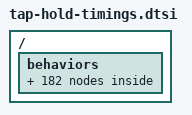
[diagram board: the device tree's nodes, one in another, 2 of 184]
#include <dt-bindings/zmk/behaviors.h>

/ {
    behaviors {

        /omit-if-no-ref/
        osm: one_shot_modifier {
            compatible = "zmk,behavior-macro-one-param";
            #binding-cells = <1>;
            tap-ms = <0>;
            wait-ms = <0>;
            bindings = <&macro_param_1to1>, <&macro_tap &sk MACRO_PLACEHOLDER>;
        };

        /omit-if-no-ref/
        osl: one_shot_layer {
            compatible = "zmk,behavior-macro-one-param";
            #binding-cells = <1>;
            tap-ms = <0>;
            wait-ms = <0>;
            bindings = <&macro_param_1to1>, <&macro_tap &sl MACRO_PLACEHOLDER>;
        };

        /omit-if-no-ref/
        mtS: mod_tap_very_slow {
            compatible = "zmk,behavior-hold-tap";
            #binding-cells = <2>;
            flavor = "hold-preferred";
            tapping-term-ms = <500>;
            bindings = <&kp>, <&kp>;
            display-name = "mod tap very slow";
        };

        /omit-if-no-ref/
        hrmS: tap_mod_very_slow {
            compatible = "zmk,behavior-hold-tap";
            #binding-cells = <2>;
            flavor = "tap-preferred";
            tapping-term-ms = <500>;
            bindings = <&kp>, <&kp>;
            display-name = "tap mod very slow";
        };

        /omit-if-no-ref/
        mts: mod_tap_slow {
            compatible = "zmk,behavior-hold-tap";
            #binding-cells = <2>;
            flavor = "hold-preferred";
            tapping-term-ms = <300>;
            bindings = <&kp>, <&kp>;
            display-name = "mod tap slow";
        };

        /omit-if-no-ref/
        hrms: tap_mod_slow {
            compatible = "zmk,behavior-hold-tap";
            #binding-cells = <2>;
            flavor = "tap-preferred";
            tapping-term-ms = <300>;
            bindings = <&kp>, <&kp>;
            display-name = "tap mod slow";
        };

        /omit-if-no-ref/
        mt: mod_tap {
            compatible = "zmk,behavior-hold-tap";
            #binding-cells = <2>;
            flavor = "hold-preferred";
            tapping-term-ms = <250>;
            bindings = <&kp>, <&kp>;
            display-name = "mod tap";
        };

        /omit-if-no-ref/
        hrm: tap_mod {
            compatible = "zmk,behavior-hold-tap";
            #binding-cells = <2>;
            flavor = "tap-preferred";
            tapping-term-ms = <250>;
            bindings = <&kp>, <&kp>;
            display-name = "tap mod";
        };

        /omit-if-no-ref/
        mtf: mod_tap_fast {
            compatible = "zmk,behavior-hold-tap";
            #binding-cells = <2>;
            flavor = "hold-preferred";
            tapping-term-ms = <200>;
            bindings = <&kp>, <&kp>;
            display-name = "mod tap fast";
        };

        /omit-if-no-ref/
        hrmf: tap_mod_fast {
            compatible = "zmk,behavior-hold-tap";
            #binding-cells = <2>;
            flavor = "tap-preferred";
            tapping-term-ms = <200>;
            bindings = <&kp>, <&kp>;
            display-name = "tap mod fast";
        };

        /omit-if-no-ref/
        mtF: mod_tap_very_fast {
            compatible = "zmk,behavior-hold-tap";
            #binding-cells = <2>;
            flavor = "hold-preferred";
            tapping-term-ms = <150>;
            bindings = <&kp>, <&kp>;
            display-name = "mod tap very fast";
        };

        /omit-if-no-ref/
        hrmF: tap_mod_very_fast {
            compatible = "zmk,behavior-hold-tap";
            #binding-cells = <2>;
            flavor = "tap-preferred";
            tapping-term-ms = <150>;
            bindings = <&kp>, <&kp>;
            display-name = "tap mod very fast";
        };

        /omit-if-no-ref/
        mtSd: mod_tap_very_slow_delayed {
            compatible = "zmk,behavior-hold-tap";
            #binding-cells = <2>;
            flavor = "hold-preferred";
            tapping-term-ms = <500>;
            require-prior-idle-ms = <125>;
            bindings = <&kp>, <&kp>;
            display-name = "mod tap very slow delayed";
        };

        /omit-if-no-ref/
        hrmSd: tap_mod_very_slow_delayed {
            compatible = "zmk,behavior-hold-tap";
            #binding-cells = <2>;
            flavor = "tap-preferred";
            tapping-term-ms = <500>;
            require-prior-idle-ms = <125>;
            bindings = <&kp>, <&kp>;
            display-name = "tap mod very slow delayed";
        };

        /omit-if-no-ref/
        mtsd: mod_tap_slow_delayed {
            compatible = "zmk,behavior-hold-tap";
            #binding-cells = <2>;
            flavor = "hold-preferred";
            tapping-term-ms = <300>;
            require-prior-idle-ms = <125>;
            bindings = <&kp>, <&kp>;
            display-name = "mod tap slow delayed";
        };

        /omit-if-no-ref/
        hrmsd: tap_mod_slow_delayed {
            compatible = "zmk,behavior-hold-tap";
            #binding-cells = <2>;
            flavor = "tap-preferred";
            tapping-term-ms = <300>;
            require-prior-idle-ms = <125>;
            bindings = <&kp>, <&kp>;
            display-name = "tap mod slow delayed";
        };

        /omit-if-no-ref/
        mtd: mod_tap_delayed {
            compatible = "zmk,behavior-hold-tap";
            #binding-cells = <2>;
            flavor = "hold-preferred";
            tapping-term-ms = <250>;
            require-prior-idle-ms = <125>;
            bindings = <&kp>, <&kp>;
            display-name = "mod tap delayed";
        };

        /omit-if-no-ref/
        hrmd: tap_mod_delayed {
            compatible = "zmk,behavior-hold-tap";
            #binding-cells = <2>;
            flavor = "tap-preferred";
            tapping-term-ms = <250>;
            require-prior-idle-ms = <125>;
            bindings = <&kp>, <&kp>;
            display-name = "tap mod delayed";
        };

        /omit-if-no-ref/
        mtfd: mod_tap_fast_delayed {
            compatible = "zmk,behavior-hold-tap";
            #binding-cells = <2>;
            flavor = "hold-preferred";
            tapping-term-ms = <200>;
            require-prior-idle-ms = <125>;
            bindings = <&kp>, <&kp>;
            display-name = "mod tap fast delayed";
        };

        /omit-if-no-ref/
        hrmfd: tap_mod_fast_delayed {
            compatible = "zmk,behavior-hold-tap";
            #binding-cells = <2>;
            flavor = "tap-preferred";
            tapping-term-ms = <200>;
            require-prior-idle-ms = <125>;
            bindings = <&kp>, <&kp>;
            display-name = "tap mod fast delayed";
        };

        /omit-if-no-ref/
        mtFd: mod_tap_very_fast_delayed {
            compatible = "zmk,behavior-hold-tap";
            #binding-cells = <2>;
            flavor = "hold-preferred";
            tapping-term-ms = <150>;
            require-prior-idle-ms = <125>;
            bindings = <&kp>, <&kp>;
            display-name = "mod tap very fast delayed";
        };

        /omit-if-no-ref/
        hrmFd: tap_mod_very_fast_delayed {
            compatible = "zmk,behavior-hold-tap";
            #binding-cells = <2>;
            flavor = "tap-preferred";
            tapping-term-ms = <150>;
            require-prior-idle-ms = <125>;
            bindings = <&kp>, <&kp>;
            display-name = "tap mod very fast delayed";
        };

        /omit-if-no-ref/
        mtSi: mod_tap_very_slow_idle {
            compatible = "zmk,behavior-hold-tap";
            #binding-cells = <2>;
            flavor = "hold-preferred";
            tapping-term-ms = <500>;
            require-prior-idle-ms = <200>;
            bindings = <&kp>, <&kp>;
            display-name = "mod tap very slow idle";
        };

        /omit-if-no-ref/
        hrmSi: tap_mod_very_slow_idle {
            compatible = "zmk,behavior-hold-tap";
            #binding-cells = <2>;
            flavor = "tap-preferred";
            tapping-term-ms = <500>;
            require-prior-idle-ms = <200>;
            bindings = <&kp>, <&kp>;
            display-name = "tap mod very slow idle";
        };

        /omit-if-no-ref/
        mtsi: mod_tap_slow_idle {
            compatible = "zmk,behavior-hold-tap";
            #binding-cells = <2>;
            flavor = "hold-preferred";
            tapping-term-ms = <300>;
            require-prior-idle-ms = <200>;
            bindings = <&kp>, <&kp>;
            display-name = "mod tap slow idle";
        };

        /omit-if-no-ref/
        hrmsi: tap_mod_slow_idle {
            compatible = "zmk,behavior-hold-tap";
            #binding-cells = <2>;
            flavor = "tap-preferred";
            tapping-term-ms = <300>;
            require-prior-idle-ms = <200>;
            bindings = <&kp>, <&kp>;
            display-name = "tap mod slow idle";
        };

        /omit-if-no-ref/
        mti: mod_tap_idle {
            compatible = "zmk,behavior-hold-tap";
            #binding-cells = <2>;
            flavor = "hold-preferred";
            tapping-term-ms = <250>;
            require-prior-idle-ms = <200>;
            bindings = <&kp>, <&kp>;
            display-name = "mod tap idle";
        };

        /omit-if-no-ref/
        hrmi: tap_mod_idle {
            compatible = "zmk,behavior-hold-tap";
            #binding-cells = <2>;
            flavor = "tap-preferred";
            tapping-term-ms = <250>;
            require-prior-idle-ms = <200>;
            bindings = <&kp>, <&kp>;
            display-name = "tap mod idle";
        };

        /omit-if-no-ref/
        mtfi: mod_tap_fast_idle {
            compatible = "zmk,behavior-hold-tap";
            #binding-cells = <2>;
            flavor = "hold-preferred";
            tapping-term-ms = <200>;
            require-prior-idle-ms = <200>;
            bindings = <&kp>, <&kp>;
            display-name = "mod tap fast idle";
        };

        /omit-if-no-ref/
        hrmfi: tap_mod_fast_idle {
            compatible = "zmk,behavior-hold-tap";
            #binding-cells = <2>;
            flavor = "tap-preferred";
            tapping-term-ms = <200>;
            require-prior-idle-ms = <200>;
            bindings = <&kp>, <&kp>;
            display-name = "tap mod fast idle";
        };

        /omit-if-no-ref/
        mtFi: mod_tap_very_fast_idle {
            compatible = "zmk,behavior-hold-tap";
            #binding-cells = <2>;
            flavor = "hold-preferred";
            tapping-term-ms = <150>;
            require-prior-idle-ms = <200>;
            bindings = <&kp>, <&kp>;
            display-name = "mod tap very fast idle";
        };

        /omit-if-no-ref/
        hrmFi: tap_mod_very_fast_idle {
            compatible = "zmk,behavior-hold-tap";
            #binding-cells = <2>;
            flavor = "tap-preferred";
            tapping-term-ms = <150>;
            require-prior-idle-ms = <200>;
            bindings = <&kp>, <&kp>;
            display-name = "tap mod very fast idle";
        };

        /omit-if-no-ref/
        mtS_sk: mod_tap_very_slow_sticky_key {
            compatible = "zmk,behavior-hold-tap";
            #binding-cells = <2>;
            flavor = "hold-preferred";
            tapping-term-ms = <500>;
            bindings = <&kp>, <&osm>;
            display-name = "mod tap very slow sticky key";
        };

        /omit-if-no-ref/
        hrmS_sk: tap_mod_very_slow_sticky_key {
            compatible = "zmk,behavior-hold-tap";
            #binding-cells = <2>;
            flavor = "tap-preferred";
            tapping-term-ms = <500>;
            bindings = <&kp>, <&osm>;
            display-name = "tap mod very slow sticky key";
        };

        /omit-if-no-ref/
        mts_sk: mod_tap_slow_sticky_key {
            compatible = "zmk,behavior-hold-tap";
            #binding-cells = <2>;
            flavor = "hold-preferred";
            tapping-term-ms = <300>;
            bindings = <&kp>, <&osm>;
            display-name = "mod tap slow sticky key";
        };

        /omit-if-no-ref/
        hrms_sk: tap_mod_slow_sticky_key {
            compatible = "zmk,behavior-hold-tap";
            #binding-cells = <2>;
            flavor = "tap-preferred";
            tapping-term-ms = <300>;
            bindings = <&kp>, <&osm>;
            display-name = "tap mod slow sticky key";
        };

        /omit-if-no-ref/
        mt_sk: mod_tap_sticky_key {
            compatible = "zmk,behavior-hold-tap";
            #binding-cells = <2>;
            flavor = "hold-preferred";
            tapping-term-ms = <250>;
            bindings = <&kp>, <&osm>;
            display-name = "mod tap sticky key";
        };

        /omit-if-no-ref/
        hrm_sk: tap_mod_sticky_key {
            compatible = "zmk,behavior-hold-tap";
            #binding-cells = <2>;
            flavor = "tap-preferred";
            tapping-term-ms = <250>;
            bindings = <&kp>, <&osm>;
            display-name = "tap mod sticky key";
        };

        /omit-if-no-ref/
        mtf_sk: mod_tap_fast_sticky_key {
            compatible = "zmk,behavior-hold-tap";
            #binding-cells = <2>;
            flavor = "hold-preferred";
            tapping-term-ms = <200>;
            bindings = <&kp>, <&osm>;
            display-name = "mod tap fast sticky key";
        };

        /omit-if-no-ref/
        hrmf_sk: tap_mod_fast_sticky_key {
            compatible = "zmk,behavior-hold-tap";
            #binding-cells = <2>;
            flavor = "tap-preferred";
            tapping-term-ms = <200>;
            bindings = <&kp>, <&osm>;
            display-name = "tap mod fast sticky key";
        };

        /omit-if-no-ref/
        mtF_sk: mod_tap_very_fast_sticky_key {
            compatible = "zmk,behavior-hold-tap";
            #binding-cells = <2>;
            flavor = "hold-preferred";
            tapping-term-ms = <150>;
            bindings = <&kp>, <&osm>;
            display-name = "mod tap very fast sticky key";
        };

        /omit-if-no-ref/
        hrmF_sk: tap_mod_very_fast_sticky_key {
            compatible = "zmk,behavior-hold-tap";
            #binding-cells = <2>;
            flavor = "tap-preferred";
            tapping-term-ms = <150>;
            bindings = <&kp>, <&osm>;
            display-name = "tap mod very fast sticky key";
        };

        /omit-if-no-ref/
        mtSd_sk: mod_tap_very_slow_delayed_sticky_key {
            compatible = "zmk,behavior-hold-tap";
            #binding-cells = <2>;
            flavor = "hold-preferred";
            tapping-term-ms = <500>;
            require-prior-idle-ms = <125>;
            bindings = <&kp>, <&osm>;
            display-name = "mod tap very slow delayed sticky key";
        };

        /omit-if-no-ref/
        hrmSd_sk: tap_mod_very_slow_delayed_sticky_key {
            compatible = "zmk,behavior-hold-tap";
            #binding-cells = <2>;
            flavor = "tap-preferred";
            tapping-term-ms = <500>;
            require-prior-idle-ms = <125>;
            bindings = <&kp>, <&osm>;
            display-name = "tap mod very slow delayed sticky key";
        };

        /omit-if-no-ref/
        mtsd_sk: mod_tap_slow_delayed_sticky_key {
            compatible = "zmk,behavior-hold-tap";
            #binding-cells = <2>;
            flavor = "hold-preferred";
            tapping-term-ms = <300>;
            require-prior-idle-ms = <125>;
            bindings = <&kp>, <&osm>;
            display-name = "mod tap slow delayed sticky key";
        };

        /omit-if-no-ref/
        hrmsd_sk: tap_mod_slow_delayed_sticky_key {
            compatible = "zmk,behavior-hold-tap";
            #binding-cells = <2>;
            flavor = "tap-preferred";
            tapping-term-ms = <300>;
            require-prior-idle-ms = <125>;
            bindings = <&kp>, <&osm>;
            display-name = "tap mod slow delayed sticky key";
        };

        /omit-if-no-ref/
        mtd_sk: mod_tap_delayed_sticky_key {
            compatible = "zmk,behavior-hold-tap";
            #binding-cells = <2>;
            flavor = "hold-preferred";
            tapping-term-ms = <250>;
            require-prior-idle-ms = <125>;
            bindings = <&kp>, <&osm>;
            display-name = "mod tap delayed sticky key";
        };

        /omit-if-no-ref/
        hrmd_sk: tap_mod_delayed_sticky_key {
            compatible = "zmk,behavior-hold-tap";
            #binding-cells = <2>;
            flavor = "tap-preferred";
            tapping-term-ms = <250>;
            require-prior-idle-ms = <125>;
            bindings = <&kp>, <&osm>;
            display-name = "tap mod delayed sticky key";
        };

        /omit-if-no-ref/
        mtfd_sk: mod_tap_fast_delayed_sticky_key {
            compatible = "zmk,behavior-hold-tap";
            #binding-cells = <2>;
            flavor = "hold-preferred";
            tapping-term-ms = <200>;
            require-prior-idle-ms = <125>;
            bindings = <&kp>, <&osm>;
            display-name = "mod tap fast delayed sticky key";
        };

        /omit-if-no-ref/
        hrmfd_sk: tap_mod_fast_delayed_sticky_key {
            compatible = "zmk,behavior-hold-tap";
            #binding-cells = <2>;
            flavor = "tap-preferred";
            tapping-term-ms = <200>;
            require-prior-idle-ms = <125>;
            bindings = <&kp>, <&osm>;
            display-name = "tap mod fast delayed sticky key";
        };

        /omit-if-no-ref/
        mtFd_sk: mod_tap_very_fast_delayed_sticky_key {
            compatible = "zmk,behavior-hold-tap";
            #binding-cells = <2>;
            flavor = "hold-preferred";
            tapping-term-ms = <150>;
            require-prior-idle-ms = <125>;
            bindings = <&kp>, <&osm>;
            display-name = "mod tap very fast delayed sticky key";
        };

        /omit-if-no-ref/
        hrmFd_sk: tap_mod_very_fast_delayed_sticky_key {
            compatible = "zmk,behavior-hold-tap";
            #binding-cells = <2>;
            flavor = "tap-preferred";
            tapping-term-ms = <150>;
            require-prior-idle-ms = <125>;
            bindings = <&kp>, <&osm>;
            display-name = "tap mod very fast delayed sticky key";
        };

        /omit-if-no-ref/
        mtSi_sk: mod_tap_very_slow_idle_sticky_key {
            compatible = "zmk,behavior-hold-tap";
            #binding-cells = <2>;
            flavor = "hold-preferred";
            tapping-term-ms = <500>;
            require-prior-idle-ms = <200>;
            bindings = <&kp>, <&osm>;
            display-name = "mod tap very slow idle sticky key";
        };

        /omit-if-no-ref/
        hrmSi_sk: tap_mod_very_slow_idle_sticky_key {
            compatible = "zmk,behavior-hold-tap";
            #binding-cells = <2>;
            flavor = "tap-preferred";
            tapping-term-ms = <500>;
            require-prior-idle-ms = <200>;
            bindings = <&kp>, <&osm>;
            display-name = "tap mod very slow idle sticky key";
        };

        /omit-if-no-ref/
        mtsi_sk: mod_tap_slow_idle_sticky_key {
            compatible = "zmk,behavior-hold-tap";
            #binding-cells = <2>;
            flavor = "hold-preferred";
            tapping-term-ms = <300>;
            require-prior-idle-ms = <200>;
            bindings = <&kp>, <&osm>;
            display-name = "mod tap slow idle sticky key";
        };

        /omit-if-no-ref/
        hrmsi_sk: tap_mod_slow_idle_sticky_key {
            compatible = "zmk,behavior-hold-tap";
            #binding-cells = <2>;
            flavor = "tap-preferred";
            tapping-term-ms = <300>;
            require-prior-idle-ms = <200>;
            bindings = <&kp>, <&osm>;
            display-name = "tap mod slow idle sticky key";
        };

        /omit-if-no-ref/
        mti_sk: mod_tap_idle_sticky_key {
            compatible = "zmk,behavior-hold-tap";
            #binding-cells = <2>;
            flavor = "hold-preferred";
            tapping-term-ms = <250>;
            require-prior-idle-ms = <200>;
            bindings = <&kp>, <&osm>;
            display-name = "mod tap idle sticky key";
        };

        /omit-if-no-ref/
        hrmi_sk: tap_mod_idle_sticky_key {
            compatible = "zmk,behavior-hold-tap";
            #binding-cells = <2>;
            flavor = "tap-preferred";
            tapping-term-ms = <250>;
            require-prior-idle-ms = <200>;
            bindings = <&kp>, <&osm>;
            display-name = "tap mod idle sticky key";
        };

        /omit-if-no-ref/
        mtfi_sk: mod_tap_fast_idle_sticky_key {
            compatible = "zmk,behavior-hold-tap";
            #binding-cells = <2>;
            flavor = "hold-preferred";
            tapping-term-ms = <200>;
            require-prior-idle-ms = <200>;
            bindings = <&kp>, <&osm>;
            display-name = "mod tap fast idle sticky key";
        };

        /omit-if-no-ref/
        hrmfi_sk: tap_mod_fast_idle_sticky_key {
            compatible = "zmk,behavior-hold-tap";
            #binding-cells = <2>;
            flavor = "tap-preferred";
            tapping-term-ms = <200>;
            require-prior-idle-ms = <200>;
            bindings = <&kp>, <&osm>;
            display-name = "tap mod fast idle sticky key";
        };

        /omit-if-no-ref/
        mtFi_sk: mod_tap_very_fast_idle_sticky_key {
            compatible = "zmk,behavior-hold-tap";
            #binding-cells = <2>;
            flavor = "hold-preferred";
            tapping-term-ms = <150>;
            require-prior-idle-ms = <200>;
            bindings = <&kp>, <&osm>;
            display-name = "mod tap very fast idle sticky key";
        };

        /omit-if-no-ref/
        hrmFi_sk: tap_mod_very_fast_idle_sticky_key {
            compatible = "zmk,behavior-hold-tap";
            #binding-cells = <2>;
            flavor = "tap-preferred";
            tapping-term-ms = <150>;
            require-prior-idle-ms = <200>;
            bindings = <&kp>, <&osm>;
            display-name = "tap mod very fast idle sticky key";
        };

        /omit-if-no-ref/
        mtS_sl: mod_tap_very_slow_sticky_layer {
            compatible = "zmk,behavior-hold-tap";
            #binding-cells = <2>;
            flavor = "hold-preferred";
            tapping-term-ms = <500>;
            bindings = <&kp>, <&osl>;
            display-name = "mod tap very slow sticky layer";
        };

        /omit-if-no-ref/
        hrmS_sl: tap_mod_very_slow_sticky_layer {
            compatible = "zmk,behavior-hold-tap";
            #binding-cells = <2>;
            flavor = "tap-preferred";
            tapping-term-ms = <500>;
            bindings = <&kp>, <&osl>;
            display-name = "tap mod very slow sticky layer";
        };

        /omit-if-no-ref/
        mts_sl: mod_tap_slow_sticky_layer {
            compatible = "zmk,behavior-hold-tap";
            #binding-cells = <2>;
            flavor = "hold-preferred";
            tapping-term-ms = <300>;
            bindings = <&kp>, <&osl>;
            display-name = "mod tap slow sticky layer";
        };

        /omit-if-no-ref/
        hrms_sl: tap_mod_slow_sticky_layer {
            compatible = "zmk,behavior-hold-tap";
            #binding-cells = <2>;
            flavor = "tap-preferred";
            tapping-term-ms = <300>;
            bindings = <&kp>, <&osl>;
            display-name = "tap mod slow sticky layer";
        };

        /omit-if-no-ref/
        mt_sl: mod_tap_sticky_layer {
            compatible = "zmk,behavior-hold-tap";
            #binding-cells = <2>;
            flavor = "hold-preferred";
            tapping-term-ms = <250>;
            bindings = <&kp>, <&osl>;
            display-name = "mod tap sticky layer";
        };

        /omit-if-no-ref/
        hrm_sl: tap_mod_sticky_layer {
            compatible = "zmk,behavior-hold-tap";
            #binding-cells = <2>;
            flavor = "tap-preferred";
            tapping-term-ms = <250>;
            bindings = <&kp>, <&osl>;
            display-name = "tap mod sticky layer";
        };

        /omit-if-no-ref/
        mtf_sl: mod_tap_fast_sticky_layer {
            compatible = "zmk,behavior-hold-tap";
            #binding-cells = <2>;
            flavor = "hold-preferred";
            tapping-term-ms = <200>;
            bindings = <&kp>, <&osl>;
            display-name = "mod tap fast sticky layer";
        };

        /omit-if-no-ref/
        hrmf_sl: tap_mod_fast_sticky_layer {
            compatible = "zmk,behavior-hold-tap";
            #binding-cells = <2>;
            flavor = "tap-preferred";
            tapping-term-ms = <200>;
            bindings = <&kp>, <&osl>;
            display-name = "tap mod fast sticky layer";
        };

        /omit-if-no-ref/
        mtF_sl: mod_tap_very_fast_sticky_layer {
            compatible = "zmk,behavior-hold-tap";
            #binding-cells = <2>;
            flavor = "hold-preferred";
            tapping-term-ms = <150>;
            bindings = <&kp>, <&osl>;
            display-name = "mod tap very fast sticky layer";
        };

        /omit-if-no-ref/
        hrmF_sl: tap_mod_very_fast_sticky_layer {
            compatible = "zmk,behavior-hold-tap";
            #binding-cells = <2>;
            flavor = "tap-preferred";
            tapping-term-ms = <150>;
            bindings = <&kp>, <&osl>;
            display-name = "tap mod very fast sticky layer";
        };

        /omit-if-no-ref/
        mtSd_sl: mod_tap_very_slow_delayed_sticky_layer {
            compatible = "zmk,behavior-hold-tap";
            #binding-cells = <2>;
            flavor = "hold-preferred";
            tapping-term-ms = <500>;
            require-prior-idle-ms = <125>;
            bindings = <&kp>, <&osl>;
            display-name = "mod tap very slow delayed sticky layer";
        };

        /omit-if-no-ref/
        hrmSd_sl: tap_mod_very_slow_delayed_sticky_layer {
            compatible = "zmk,behavior-hold-tap";
            #binding-cells = <2>;
            flavor = "tap-preferred";
            tapping-term-ms = <500>;
            require-prior-idle-ms = <125>;
            bindings = <&kp>, <&osl>;
            display-name = "tap mod very slow delayed sticky layer";
        };

        /omit-if-no-ref/
        mtsd_sl: mod_tap_slow_delayed_sticky_layer {
            compatible = "zmk,behavior-hold-tap";
            #binding-cells = <2>;
            flavor = "hold-preferred";
            tapping-term-ms = <300>;
            require-prior-idle-ms = <125>;
            bindings = <&kp>, <&osl>;
            display-name = "mod tap slow delayed sticky layer";
        };

        /omit-if-no-ref/
        hrmsd_sl: tap_mod_slow_delayed_sticky_layer {
            compatible = "zmk,behavior-hold-tap";
            #binding-cells = <2>;
            flavor = "tap-preferred";
            tapping-term-ms = <300>;
            require-prior-idle-ms = <125>;
            bindings = <&kp>, <&osl>;
            display-name = "tap mod slow delayed sticky layer";
        };

        /omit-if-no-ref/
        mtd_sl: mod_tap_delayed_sticky_layer {
            compatible = "zmk,behavior-hold-tap";
            #binding-cells = <2>;
            flavor = "hold-preferred";
            tapping-term-ms = <250>;
            require-prior-idle-ms = <125>;
            bindings = <&kp>, <&osl>;
            display-name = "mod tap delayed sticky layer";
        };

        /omit-if-no-ref/
        hrmd_sl: tap_mod_delayed_sticky_layer {
            compatible = "zmk,behavior-hold-tap";
            #binding-cells = <2>;
            flavor = "tap-preferred";
            tapping-term-ms = <250>;
            require-prior-idle-ms = <125>;
            bindings = <&kp>, <&osl>;
            display-name = "tap mod delayed sticky layer";
        };

        /omit-if-no-ref/
        mtfd_sl: mod_tap_fast_delayed_sticky_layer {
            compatible = "zmk,behavior-hold-tap";
            #binding-cells = <2>;
            flavor = "hold-preferred";
            tapping-term-ms = <200>;
            require-prior-idle-ms = <125>;
            bindings = <&kp>, <&osl>;
            display-name = "mod tap fast delayed sticky layer";
        };

        /omit-if-no-ref/
        hrmfd_sl: tap_mod_fast_delayed_sticky_layer {
            compatible = "zmk,behavior-hold-tap";
            #binding-cells = <2>;
            flavor = "tap-preferred";
            tapping-term-ms = <200>;
            require-prior-idle-ms = <125>;
            bindings = <&kp>, <&osl>;
            display-name = "tap mod fast delayed sticky layer";
        };

        /omit-if-no-ref/
        mtFd_sl: mod_tap_very_fast_delayed_sticky_layer {
            compatible = "zmk,behavior-hold-tap";
            #binding-cells = <2>;
            flavor = "hold-preferred";
            tapping-term-ms = <150>;
            require-prior-idle-ms = <125>;
            bindings = <&kp>, <&osl>;
            display-name = "mod tap very fast delayed sticky layer";
        };

        /omit-if-no-ref/
        hrmFd_sl: tap_mod_very_fast_delayed_sticky_layer {
            compatible = "zmk,behavior-hold-tap";
            #binding-cells = <2>;
            flavor = "tap-preferred";
            tapping-term-ms = <150>;
            require-prior-idle-ms = <125>;
            bindings = <&kp>, <&osl>;
            display-name = "tap mod very fast delayed sticky layer";
        };

        /omit-if-no-ref/
        mtSi_sl: mod_tap_very_slow_idle_sticky_layer {
            compatible = "zmk,behavior-hold-tap";
            #binding-cells = <2>;
            flavor = "hold-preferred";
            tapping-term-ms = <500>;
            require-prior-idle-ms = <200>;
            bindings = <&kp>, <&osl>;
            display-name = "mod tap very slow idle sticky layer";
        };

        /omit-if-no-ref/
        hrmSi_sl: tap_mod_very_slow_idle_sticky_layer {
            compatible = "zmk,behavior-hold-tap";
            #binding-cells = <2>;
            flavor = "tap-preferred";
            tapping-term-ms = <500>;
            require-prior-idle-ms = <200>;
            bindings = <&kp>, <&osl>;
            display-name = "tap mod very slow idle sticky layer";
        };

        /omit-if-no-ref/
        mtsi_sl: mod_tap_slow_idle_sticky_layer {
            compatible = "zmk,behavior-hold-tap";
            #binding-cells = <2>;
            flavor = "hold-preferred";
            tapping-term-ms = <300>;
            require-prior-idle-ms = <200>;
            bindings = <&kp>, <&osl>;
            display-name = "mod tap slow idle sticky layer";
        };

        /omit-if-no-ref/
        hrmsi_sl: tap_mod_slow_idle_sticky_layer {
            compatible = "zmk,behavior-hold-tap";
            #binding-cells = <2>;
            flavor = "tap-preferred";
            tapping-term-ms = <300>;
            require-prior-idle-ms = <200>;
            bindings = <&kp>, <&osl>;
            display-name = "tap mod slow idle sticky layer";
        };

        /omit-if-no-ref/
        mti_sl: mod_tap_idle_sticky_layer {
            compatible = "zmk,behavior-hold-tap";
            #binding-cells = <2>;
            flavor = "hold-preferred";
            tapping-term-ms = <250>;
            require-prior-idle-ms = <200>;
            bindings = <&kp>, <&osl>;
            display-name = "mod tap idle sticky layer";
        };

        /omit-if-no-ref/
        hrmi_sl: tap_mod_idle_sticky_layer {
            compatible = "zmk,behavior-hold-tap";
            #binding-cells = <2>;
            flavor = "tap-preferred";
            tapping-term-ms = <250>;
            require-prior-idle-ms = <200>;
            bindings = <&kp>, <&osl>;
            display-name = "tap mod idle sticky layer";
        };

        /omit-if-no-ref/
        mtfi_sl: mod_tap_fast_idle_sticky_layer {
            compatible = "zmk,behavior-hold-tap";
            #binding-cells = <2>;
            flavor = "hold-preferred";
            tapping-term-ms = <200>;
            require-prior-idle-ms = <200>;
            bindings = <&kp>, <&osl>;
            display-name = "mod tap fast idle sticky layer";
        };

        /omit-if-no-ref/
        hrmfi_sl: tap_mod_fast_idle_sticky_layer {
            compatible = "zmk,behavior-hold-tap";
            #binding-cells = <2>;
            flavor = "tap-preferred";
            tapping-term-ms = <200>;
            require-prior-idle-ms = <200>;
            bindings = <&kp>, <&osl>;
            display-name = "tap mod fast idle sticky layer";
        };

        /omit-if-no-ref/
        mtFi_sl: mod_tap_very_fast_idle_sticky_layer {
            compatible = "zmk,behavior-hold-tap";
            #binding-cells = <2>;
            flavor = "hold-preferred";
            tapping-term-ms = <150>;
            require-prior-idle-ms = <200>;
            bindings = <&kp>, <&osl>;
            display-name = "mod tap very fast idle sticky layer";
        };

        /omit-if-no-ref/
        hrmFi_sl: tap_mod_very_fast_idle_sticky_layer {
            compatible = "zmk,behavior-hold-tap";
            #binding-cells = <2>;
            flavor = "tap-preferred";
            tapping-term-ms = <150>;
            require-prior-idle-ms = <200>;
            bindings = <&kp>, <&osl>;
            display-name = "tap mod very fast idle sticky layer";
        };

        /omit-if-no-ref/
        ltS: layer_tap_very_slow {
            compatible = "zmk,behavior-hold-tap";
            #binding-cells = <2>;
            flavor = "hold-preferred";
            tapping-term-ms = <500>;
            bindings = <&mo>, <&kp>;
            display-name = "layer tap very slow";
        };

        /omit-if-no-ref/
        hrlS: tap_layer_very_slow {
            compatible = "zmk,behavior-hold-tap";
            #binding-cells = <2>;
            flavor = "tap-preferred";
            tapping-term-ms = <500>;
            bindings = <&mo>, <&kp>;
            display-name = "tap layer very slow";
        };

        /omit-if-no-ref/
        lts: layer_tap_slow {
            compatible = "zmk,behavior-hold-tap";
            #binding-cells = <2>;
            flavor = "hold-preferred";
            tapping-term-ms = <300>;
            bindings = <&mo>, <&kp>;
            display-name = "layer tap slow";
        };

        /omit-if-no-ref/
        hrls: tap_layer_slow {
            compatible = "zmk,behavior-hold-tap";
            #binding-cells = <2>;
            flavor = "tap-preferred";
            tapping-term-ms = <300>;
            bindings = <&mo>, <&kp>;
            display-name = "tap layer slow";
        };

        /omit-if-no-ref/
        lt: layer_tap {
            compatible = "zmk,behavior-hold-tap";
            #binding-cells = <2>;
            flavor = "hold-preferred";
            tapping-term-ms = <250>;
            bindings = <&mo>, <&kp>;
            display-name = "layer tap";
        };

        /omit-if-no-ref/
        hrl: tap_layer {
            compatible = "zmk,behavior-hold-tap";
            #binding-cells = <2>;
            flavor = "tap-preferred";
            tapping-term-ms = <250>;
            bindings = <&mo>, <&kp>;
            display-name = "tap layer";
        };

        /omit-if-no-ref/
        ltf: layer_tap_fast {
            compatible = "zmk,behavior-hold-tap";
            #binding-cells = <2>;
            flavor = "hold-preferred";
            tapping-term-ms = <200>;
            bindings = <&mo>, <&kp>;
            display-name = "layer tap fast";
        };

        /omit-if-no-ref/
        hrlf: tap_layer_fast {
            compatible = "zmk,behavior-hold-tap";
            #binding-cells = <2>;
            flavor = "tap-preferred";
            tapping-term-ms = <200>;
            bindings = <&mo>, <&kp>;
            display-name = "tap layer fast";
        };

        /omit-if-no-ref/
        ltF: layer_tap_very_fast {
            compatible = "zmk,behavior-hold-tap";
            #binding-cells = <2>;
            flavor = "hold-preferred";
            tapping-term-ms = <150>;
            bindings = <&mo>, <&kp>;
            display-name = "layer tap very fast";
        };

        /omit-if-no-ref/
        hrlF: tap_layer_very_fast {
            compatible = "zmk,behavior-hold-tap";
            #binding-cells = <2>;
            flavor = "tap-preferred";
            tapping-term-ms = <150>;
            bindings = <&mo>, <&kp>;
            display-name = "tap layer very fast";
        };

        /omit-if-no-ref/
        ltSd: layer_tap_very_slow_delayed {
            compatible = "zmk,behavior-hold-tap";
            #binding-cells = <2>;
            flavor = "hold-preferred";
            tapping-term-ms = <500>;
            require-prior-idle-ms = <125>;
            bindings = <&mo>, <&kp>;
            display-name = "layer tap very slow delayed";
        };

        /omit-if-no-ref/
        hrlSd: tap_layer_very_slow_delayed {
            compatible = "zmk,behavior-hold-tap";
            #binding-cells = <2>;
            flavor = "tap-preferred";
            tapping-term-ms = <500>;
            require-prior-idle-ms = <125>;
            bindings = <&mo>, <&kp>;
            display-name = "tap layer very slow delayed";
        };

        /omit-if-no-ref/
        ltsd: layer_tap_slow_delayed {
            compatible = "zmk,behavior-hold-tap";
            #binding-cells = <2>;
            flavor = "hold-preferred";
            tapping-term-ms = <300>;
            require-prior-idle-ms = <125>;
            bindings = <&mo>, <&kp>;
            display-name = "layer tap slow delayed";
        };

        /omit-if-no-ref/
        hrlsd: tap_layer_slow_delayed {
            compatible = "zmk,behavior-hold-tap";
            #binding-cells = <2>;
            flavor = "tap-preferred";
            tapping-term-ms = <300>;
            require-prior-idle-ms = <125>;
            bindings = <&mo>, <&kp>;
            display-name = "tap layer slow delayed";
        };

        /omit-if-no-ref/
        ltd: layer_tap_delayed {
            compatible = "zmk,behavior-hold-tap";
            #binding-cells = <2>;
            flavor = "hold-preferred";
            tapping-term-ms = <250>;
            require-prior-idle-ms = <125>;
            bindings = <&mo>, <&kp>;
            display-name = "layer tap delayed";
        };

        /omit-if-no-ref/
        hrld: tap_layer_delayed {
            compatible = "zmk,behavior-hold-tap";
            #binding-cells = <2>;
            flavor = "tap-preferred";
            tapping-term-ms = <250>;
            require-prior-idle-ms = <125>;
            bindings = <&mo>, <&kp>;
            display-name = "tap layer delayed";
        };

        /omit-if-no-ref/
        ltfd: layer_tap_fast_delayed {
            compatible = "zmk,behavior-hold-tap";
            #binding-cells = <2>;
            flavor = "hold-preferred";
            tapping-term-ms = <200>;
            require-prior-idle-ms = <125>;
            bindings = <&mo>, <&kp>;
            display-name = "layer tap fast delayed";
        };

        /omit-if-no-ref/
        hrlfd: tap_layer_fast_delayed {
            compatible = "zmk,behavior-hold-tap";
            #binding-cells = <2>;
            flavor = "tap-preferred";
            tapping-term-ms = <200>;
            require-prior-idle-ms = <125>;
            bindings = <&mo>, <&kp>;
            display-name = "tap layer fast delayed";
        };

        /omit-if-no-ref/
        ltFd: layer_tap_very_fast_delayed {
            compatible = "zmk,behavior-hold-tap";
            #binding-cells = <2>;
            flavor = "hold-preferred";
            tapping-term-ms = <150>;
            require-prior-idle-ms = <125>;
            bindings = <&mo>, <&kp>;
            display-name = "layer tap very fast delayed";
        };

        /omit-if-no-ref/
        hrlFd: tap_layer_very_fast_delayed {
            compatible = "zmk,behavior-hold-tap";
            #binding-cells = <2>;
            flavor = "tap-preferred";
            tapping-term-ms = <150>;
            require-prior-idle-ms = <125>;
            bindings = <&mo>, <&kp>;
            display-name = "tap layer very fast delayed";
        };

        /omit-if-no-ref/
        ltSi: layer_tap_very_slow_idle {
            compatible = "zmk,behavior-hold-tap";
            #binding-cells = <2>;
            flavor = "hold-preferred";
            tapping-term-ms = <500>;
            require-prior-idle-ms = <200>;
            bindings = <&mo>, <&kp>;
            display-name = "layer tap very slow idle";
        };

        /omit-if-no-ref/
        hrlSi: tap_layer_very_slow_idle {
            compatible = "zmk,behavior-hold-tap";
            #binding-cells = <2>;
            flavor = "tap-preferred";
            tapping-term-ms = <500>;
            require-prior-idle-ms = <200>;
            bindings = <&mo>, <&kp>;
            display-name = "tap layer very slow idle";
        };

        /omit-if-no-ref/
        ltsi: layer_tap_slow_idle {
            compatible = "zmk,behavior-hold-tap";
            #binding-cells = <2>;
            flavor = "hold-preferred";
            tapping-term-ms = <300>;
            require-prior-idle-ms = <200>;
            bindings = <&mo>, <&kp>;
            display-name = "layer tap slow idle";
        };

        /omit-if-no-ref/
        hrlsi: tap_layer_slow_idle {
            compatible = "zmk,behavior-hold-tap";
            #binding-cells = <2>;
            flavor = "tap-preferred";
            tapping-term-ms = <300>;
            require-prior-idle-ms = <200>;
            bindings = <&mo>, <&kp>;
            display-name = "tap layer slow idle";
        };

        /omit-if-no-ref/
        lti: layer_tap_idle {
            compatible = "zmk,behavior-hold-tap";
            #binding-cells = <2>;
            flavor = "hold-preferred";
            tapping-term-ms = <250>;
            require-prior-idle-ms = <200>;
            bindings = <&mo>, <&kp>;
            display-name = "layer tap idle";
        };

        /omit-if-no-ref/
        hrli: tap_layer_idle {
            compatible = "zmk,behavior-hold-tap";
            #binding-cells = <2>;
            flavor = "tap-preferred";
            tapping-term-ms = <250>;
            require-prior-idle-ms = <200>;
            bindings = <&mo>, <&kp>;
            display-name = "tap layer idle";
        };

        /omit-if-no-ref/
        ltfi: layer_tap_fast_idle {
            compatible = "zmk,behavior-hold-tap";
            #binding-cells = <2>;
            flavor = "hold-preferred";
            tapping-term-ms = <200>;
            require-prior-idle-ms = <200>;
            bindings = <&mo>, <&kp>;
            display-name = "layer tap fast idle";
        };

        /omit-if-no-ref/
        hrlfi: tap_layer_fast_idle {
            compatible = "zmk,behavior-hold-tap";
            #binding-cells = <2>;
            flavor = "tap-preferred";
            tapping-term-ms = <200>;
            require-prior-idle-ms = <200>;
            bindings = <&mo>, <&kp>;
            display-name = "tap layer fast idle";
        };

        /omit-if-no-ref/
        ltFi: layer_tap_very_fast_idle {
            compatible = "zmk,behavior-hold-tap";
            #binding-cells = <2>;
            flavor = "hold-preferred";
            tapping-term-ms = <150>;
            require-prior-idle-ms = <200>;
            bindings = <&mo>, <&kp>;
            display-name = "layer tap very fast idle";
        };

        /omit-if-no-ref/
        hrlFi: tap_layer_very_fast_idle {
            compatible = "zmk,behavior-hold-tap";
            #binding-cells = <2>;
            flavor = "tap-preferred";
            tapping-term-ms = <150>;
            require-prior-idle-ms = <200>;
            bindings = <&mo>, <&kp>;
            display-name = "tap layer very fast idle";
        };

        /omit-if-no-ref/
        ltS_sk: layer_tap_very_slow_sticky_key {
            compatible = "zmk,behavior-hold-tap";
            #binding-cells = <2>;
            flavor = "hold-preferred";
            tapping-term-ms = <500>;
            bindings = <&mo>, <&osm>;
            display-name = "layer tap very slow sticky key";
        };

        /omit-if-no-ref/
        hrlS_sk: tap_layer_very_slow_sticky_key {
            compatible = "zmk,behavior-hold-tap";
            #binding-cells = <2>;
            flavor = "tap-preferred";
            tapping-term-ms = <500>;
            bindings = <&mo>, <&osm>;
            display-name = "tap layer very slow sticky key";
        };

        /omit-if-no-ref/
        lts_sk: layer_tap_slow_sticky_key {
            compatible = "zmk,behavior-hold-tap";
            #binding-cells = <2>;
            flavor = "hold-preferred";
            tapping-term-ms = <300>;
            bindings = <&mo>, <&osm>;
            display-name = "layer tap slow sticky key";
        };

        /omit-if-no-ref/
        hrls_sk: tap_layer_slow_sticky_key {
            compatible = "zmk,behavior-hold-tap";
            #binding-cells = <2>;
            flavor = "tap-preferred";
            tapping-term-ms = <300>;
            bindings = <&mo>, <&osm>;
            display-name = "tap layer slow sticky key";
        };

        /omit-if-no-ref/
        lt_sk: layer_tap_sticky_key {
            compatible = "zmk,behavior-hold-tap";
            #binding-cells = <2>;
            flavor = "hold-preferred";
            tapping-term-ms = <250>;
            bindings = <&mo>, <&osm>;
            display-name = "layer tap sticky key";
        };

        /omit-if-no-ref/
        hrl_sk: tap_layer_sticky_key {
            compatible = "zmk,behavior-hold-tap";
            #binding-cells = <2>;
            flavor = "tap-preferred";
            tapping-term-ms = <250>;
            bindings = <&mo>, <&osm>;
            display-name = "tap layer sticky key";
        };

        /omit-if-no-ref/
        ltf_sk: layer_tap_fast_sticky_key {
            compatible = "zmk,behavior-hold-tap";
            #binding-cells = <2>;
            flavor = "hold-preferred";
            tapping-term-ms = <200>;
            bindings = <&mo>, <&osm>;
            display-name = "layer tap fast sticky key";
        };

        /omit-if-no-ref/
        hrlf_sk: tap_layer_fast_sticky_key {
            compatible = "zmk,behavior-hold-tap";
            #binding-cells = <2>;
            flavor = "tap-preferred";
            tapping-term-ms = <200>;
            bindings = <&mo>, <&osm>;
            display-name = "tap layer fast sticky key";
        };

        /omit-if-no-ref/
        ltF_sk: layer_tap_very_fast_sticky_key {
            compatible = "zmk,behavior-hold-tap";
            #binding-cells = <2>;
            flavor = "hold-preferred";
            tapping-term-ms = <150>;
            bindings = <&mo>, <&osm>;
            display-name = "layer tap very fast sticky key";
        };

        /omit-if-no-ref/
        hrlF_sk: tap_layer_very_fast_sticky_key {
            compatible = "zmk,behavior-hold-tap";
            #binding-cells = <2>;
            flavor = "tap-preferred";
            tapping-term-ms = <150>;
            bindings = <&mo>, <&osm>;
            display-name = "tap layer very fast sticky key";
        };

        /omit-if-no-ref/
        ltSd_sk: layer_tap_very_slow_delayed_sticky_key {
            compatible = "zmk,behavior-hold-tap";
            #binding-cells = <2>;
            flavor = "hold-preferred";
            tapping-term-ms = <500>;
            require-prior-idle-ms = <125>;
            bindings = <&mo>, <&osm>;
            display-name = "layer tap very slow delayed sticky key";
        };

        /omit-if-no-ref/
        hrlSd_sk: tap_layer_very_slow_delayed_sticky_key {
            compatible = "zmk,behavior-hold-tap";
            #binding-cells = <2>;
            flavor = "tap-preferred";
            tapping-term-ms = <500>;
            require-prior-idle-ms = <125>;
            bindings = <&mo>, <&osm>;
            display-name = "tap layer very slow delayed sticky key";
        };

        /omit-if-no-ref/
        ltsd_sk: layer_tap_slow_delayed_sticky_key {
            compatible = "zmk,behavior-hold-tap";
            #binding-cells = <2>;
            flavor = "hold-preferred";
            tapping-term-ms = <300>;
            require-prior-idle-ms = <125>;
            bindings = <&mo>, <&osm>;
            display-name = "layer tap slow delayed sticky key";
        };

        /omit-if-no-ref/
        hrlsd_sk: tap_layer_slow_delayed_sticky_key {
            compatible = "zmk,behavior-hold-tap";
            #binding-cells = <2>;
            flavor = "tap-preferred";
            tapping-term-ms = <300>;
            require-prior-idle-ms = <125>;
            bindings = <&mo>, <&osm>;
            display-name = "tap layer slow delayed sticky key";
        };

        /omit-if-no-ref/
        ltd_sk: layer_tap_delayed_sticky_key {
            compatible = "zmk,behavior-hold-tap";
            #binding-cells = <2>;
            flavor = "hold-preferred";
            tapping-term-ms = <250>;
            require-prior-idle-ms = <125>;
            bindings = <&mo>, <&osm>;
            display-name = "layer tap delayed sticky key";
        };

        /omit-if-no-ref/
        hrld_sk: tap_layer_delayed_sticky_key {
            compatible = "zmk,behavior-hold-tap";
            #binding-cells = <2>;
            flavor = "tap-preferred";
            tapping-term-ms = <250>;
            require-prior-idle-ms = <125>;
            bindings = <&mo>, <&osm>;
            display-name = "tap layer delayed sticky key";
        };

        /omit-if-no-ref/
        ltfd_sk: layer_tap_fast_delayed_sticky_key {
            compatible = "zmk,behavior-hold-tap";
            #binding-cells = <2>;
            flavor = "hold-preferred";
            tapping-term-ms = <200>;
            require-prior-idle-ms = <125>;
            bindings = <&mo>, <&osm>;
            display-name = "layer tap fast delayed sticky key";
        };

        /omit-if-no-ref/
        hrlfd_sk: tap_layer_fast_delayed_sticky_key {
            compatible = "zmk,behavior-hold-tap";
            #binding-cells = <2>;
            flavor = "tap-preferred";
            tapping-term-ms = <200>;
            require-prior-idle-ms = <125>;
            bindings = <&mo>, <&osm>;
            display-name = "tap layer fast delayed sticky key";
        };

        /omit-if-no-ref/
        ltFd_sk: layer_tap_very_fast_delayed_sticky_key {
            compatible = "zmk,behavior-hold-tap";
            #binding-cells = <2>;
            flavor = "hold-preferred";
            tapping-term-ms = <150>;
            require-prior-idle-ms = <125>;
            bindings = <&mo>, <&osm>;
            display-name = "layer tap very fast delayed sticky key";
        };

        /omit-if-no-ref/
        hrlFd_sk: tap_layer_very_fast_delayed_sticky_key {
            compatible = "zmk,behavior-hold-tap";
            #binding-cells = <2>;
            flavor = "tap-preferred";
            tapping-term-ms = <150>;
            require-prior-idle-ms = <125>;
            bindings = <&mo>, <&osm>;
            display-name = "tap layer very fast delayed sticky key";
        };

        /omit-if-no-ref/
        ltSi_sk: layer_tap_very_slow_idle_sticky_key {
            compatible = "zmk,behavior-hold-tap";
            #binding-cells = <2>;
            flavor = "hold-preferred";
            tapping-term-ms = <500>;
            require-prior-idle-ms = <200>;
            bindings = <&mo>, <&osm>;
            display-name = "layer tap very slow idle sticky key";
        };

        /omit-if-no-ref/
        hrlSi_sk: tap_layer_very_slow_idle_sticky_key {
            compatible = "zmk,behavior-hold-tap";
            #binding-cells = <2>;
            flavor = "tap-preferred";
            tapping-term-ms = <500>;
            require-prior-idle-ms = <200>;
            bindings = <&mo>, <&osm>;
            display-name = "tap layer very slow idle sticky key";
        };

        /omit-if-no-ref/
        ltsi_sk: layer_tap_slow_idle_sticky_key {
            compatible = "zmk,behavior-hold-tap";
            #binding-cells = <2>;
            flavor = "hold-preferred";
            tapping-term-ms = <300>;
            require-prior-idle-ms = <200>;
            bindings = <&mo>, <&osm>;
            display-name = "layer tap slow idle sticky key";
        };

        /omit-if-no-ref/
        hrlsi_sk: tap_layer_slow_idle_sticky_key {
            compatible = "zmk,behavior-hold-tap";
            #binding-cells = <2>;
            flavor = "tap-preferred";
            tapping-term-ms = <300>;
            require-prior-idle-ms = <200>;
            bindings = <&mo>, <&osm>;
            display-name = "tap layer slow idle sticky key";
        };

        /omit-if-no-ref/
        lti_sk: layer_tap_idle_sticky_key {
            compatible = "zmk,behavior-hold-tap";
            #binding-cells = <2>;
            flavor = "hold-preferred";
            tapping-term-ms = <250>;
            require-prior-idle-ms = <200>;
            bindings = <&mo>, <&osm>;
            display-name = "layer tap idle sticky key";
        };

        /omit-if-no-ref/
        hrli_sk: tap_layer_idle_sticky_key {
            compatible = "zmk,behavior-hold-tap";
            #binding-cells = <2>;
            flavor = "tap-preferred";
            tapping-term-ms = <250>;
            require-prior-idle-ms = <200>;
            bindings = <&mo>, <&osm>;
            display-name = "tap layer idle sticky key";
        };

        /omit-if-no-ref/
        ltfi_sk: layer_tap_fast_idle_sticky_key {
            compatible = "zmk,behavior-hold-tap";
            #binding-cells = <2>;
            flavor = "hold-preferred";
            tapping-term-ms = <200>;
            require-prior-idle-ms = <200>;
            bindings = <&mo>, <&osm>;
            display-name = "layer tap fast idle sticky key";
        };

        /omit-if-no-ref/
        hrlfi_sk: tap_layer_fast_idle_sticky_key {
            compatible = "zmk,behavior-hold-tap";
            #binding-cells = <2>;
            flavor = "tap-preferred";
            tapping-term-ms = <200>;
            require-prior-idle-ms = <200>;
            bindings = <&mo>, <&osm>;
            display-name = "tap layer fast idle sticky key";
        };

        /omit-if-no-ref/
        ltFi_sk: layer_tap_very_fast_idle_sticky_key {
            compatible = "zmk,behavior-hold-tap";
            #binding-cells = <2>;
            flavor = "hold-preferred";
            tapping-term-ms = <150>;
            require-prior-idle-ms = <200>;
            bindings = <&mo>, <&osm>;
            display-name = "layer tap very fast idle sticky key";
        };

        /omit-if-no-ref/
        hrlFi_sk: tap_layer_very_fast_idle_sticky_key {
            compatible = "zmk,behavior-hold-tap";
            #binding-cells = <2>;
            flavor = "tap-preferred";
            tapping-term-ms = <150>;
            require-prior-idle-ms = <200>;
            bindings = <&mo>, <&osm>;
            display-name = "tap layer very fast idle sticky key";
        };

        /omit-if-no-ref/
        ltS_sl: layer_tap_very_slow_sticky_layer {
            compatible = "zmk,behavior-hold-tap";
            #binding-cells = <2>;
            flavor = "hold-preferred";
            tapping-term-ms = <500>;
            bindings = <&mo>, <&osl>;
            display-name = "layer tap very slow sticky layer";
        };

        /omit-if-no-ref/
        hrlS_sl: tap_layer_very_slow_sticky_layer {
            compatible = "zmk,behavior-hold-tap";
            #binding-cells = <2>;
            flavor = "tap-preferred";
            tapping-term-ms = <500>;
            bindings = <&mo>, <&osl>;
            display-name = "tap layer very slow sticky layer";
        };

        /omit-if-no-ref/
        lts_sl: layer_tap_slow_sticky_layer {
            compatible = "zmk,behavior-hold-tap";
            #binding-cells = <2>;
            flavor = "hold-preferred";
            tapping-term-ms = <300>;
            bindings = <&mo>, <&osl>;
            display-name = "layer tap slow sticky layer";
        };

        /omit-if-no-ref/
        hrls_sl: tap_layer_slow_sticky_layer {
            compatible = "zmk,behavior-hold-tap";
            #binding-cells = <2>;
            flavor = "tap-preferred";
            tapping-term-ms = <300>;
            bindings = <&mo>, <&osl>;
            display-name = "tap layer slow sticky layer";
        };

        /omit-if-no-ref/
        lt_sl: layer_tap_sticky_layer {
            compatible = "zmk,behavior-hold-tap";
            #binding-cells = <2>;
            flavor = "hold-preferred";
            tapping-term-ms = <250>;
            bindings = <&mo>, <&osl>;
            display-name = "layer tap sticky layer";
        };

        /omit-if-no-ref/
        hrl_sl: tap_layer_sticky_layer {
            compatible = "zmk,behavior-hold-tap";
            #binding-cells = <2>;
            flavor = "tap-preferred";
            tapping-term-ms = <250>;
            bindings = <&mo>, <&osl>;
            display-name = "tap layer sticky layer";
        };

        /omit-if-no-ref/
        ltf_sl: layer_tap_fast_sticky_layer {
            compatible = "zmk,behavior-hold-tap";
            #binding-cells = <2>;
            flavor = "hold-preferred";
            tapping-term-ms = <200>;
            bindings = <&mo>, <&osl>;
            display-name = "layer tap fast sticky layer";
        };

        /omit-if-no-ref/
        hrlf_sl: tap_layer_fast_sticky_layer {
            compatible = "zmk,behavior-hold-tap";
            #binding-cells = <2>;
            flavor = "tap-preferred";
            tapping-term-ms = <200>;
            bindings = <&mo>, <&osl>;
            display-name = "tap layer fast sticky layer";
        };

        /omit-if-no-ref/
        ltF_sl: layer_tap_very_fast_sticky_layer {
            compatible = "zmk,behavior-hold-tap";
            #binding-cells = <2>;
            flavor = "hold-preferred";
            tapping-term-ms = <150>;
            bindings = <&mo>, <&osl>;
            display-name = "layer tap very fast sticky layer";
        };

        /omit-if-no-ref/
        hrlF_sl: tap_layer_very_fast_sticky_layer {
            compatible = "zmk,behavior-hold-tap";
            #binding-cells = <2>;
            flavor = "tap-preferred";
            tapping-term-ms = <150>;
            bindings = <&mo>, <&osl>;
            display-name = "tap layer very fast sticky layer";
        };

        /omit-if-no-ref/
        ltSd_sl: layer_tap_very_slow_delayed_sticky_layer {
            compatible = "zmk,behavior-hold-tap";
            #binding-cells = <2>;
            flavor = "hold-preferred";
            tapping-term-ms = <500>;
            require-prior-idle-ms = <125>;
            bindings = <&mo>, <&osl>;
            display-name = "layer tap very slow delayed sticky layer";
        };

        /omit-if-no-ref/
        hrlSd_sl: tap_layer_very_slow_delayed_sticky_layer {
            compatible = "zmk,behavior-hold-tap";
            #binding-cells = <2>;
            flavor = "tap-preferred";
            tapping-term-ms = <500>;
            require-prior-idle-ms = <125>;
            bindings = <&mo>, <&osl>;
            display-name = "tap layer very slow delayed sticky layer";
        };

        /omit-if-no-ref/
        ltsd_sl: layer_tap_slow_delayed_sticky_layer {
            compatible = "zmk,behavior-hold-tap";
            #binding-cells = <2>;
            flavor = "hold-preferred";
            tapping-term-ms = <300>;
            require-prior-idle-ms = <125>;
            bindings = <&mo>, <&osl>;
            display-name = "layer tap slow delayed sticky layer";
        };

        /omit-if-no-ref/
        hrlsd_sl: tap_layer_slow_delayed_sticky_layer {
            compatible = "zmk,behavior-hold-tap";
            #binding-cells = <2>;
            flavor = "tap-preferred";
            tapping-term-ms = <300>;
            require-prior-idle-ms = <125>;
            bindings = <&mo>, <&osl>;
            display-name = "tap layer slow delayed sticky layer";
        };

        /omit-if-no-ref/
        ltd_sl: layer_tap_delayed_sticky_layer {
            compatible = "zmk,behavior-hold-tap";
            #binding-cells = <2>;
            flavor = "hold-preferred";
            tapping-term-ms = <250>;
            require-prior-idle-ms = <125>;
            bindings = <&mo>, <&osl>;
            display-name = "layer tap delayed sticky layer";
        };

        /omit-if-no-ref/
        hrld_sl: tap_layer_delayed_sticky_layer {
            compatible = "zmk,behavior-hold-tap";
            #binding-cells = <2>;
            flavor = "tap-preferred";
            tapping-term-ms = <250>;
            require-prior-idle-ms = <125>;
            bindings = <&mo>, <&osl>;
            display-name = "tap layer delayed sticky layer";
        };

        /omit-if-no-ref/
        ltfd_sl: layer_tap_fast_delayed_sticky_layer {
            compatible = "zmk,behavior-hold-tap";
            #binding-cells = <2>;
            flavor = "hold-preferred";
            tapping-term-ms = <200>;
            require-prior-idle-ms = <125>;
            bindings = <&mo>, <&osl>;
            display-name = "layer tap fast delayed sticky layer";
        };

        /omit-if-no-ref/
        hrlfd_sl: tap_layer_fast_delayed_sticky_layer {
            compatible = "zmk,behavior-hold-tap";
            #binding-cells = <2>;
            flavor = "tap-preferred";
            tapping-term-ms = <200>;
            require-prior-idle-ms = <125>;
            bindings = <&mo>, <&osl>;
            display-name = "tap layer fast delayed sticky layer";
        };

        /omit-if-no-ref/
        ltFd_sl: layer_tap_very_fast_delayed_sticky_layer {
            compatible = "zmk,behavior-hold-tap";
            #binding-cells = <2>;
            flavor = "hold-preferred";
            tapping-term-ms = <150>;
            require-prior-idle-ms = <125>;
            bindings = <&mo>, <&osl>;
            display-name = "layer tap very fast delayed sticky layer";
        };

        /omit-if-no-ref/
        hrlFd_sl: tap_layer_very_fast_delayed_sticky_layer {
            compatible = "zmk,behavior-hold-tap";
            #binding-cells = <2>;
            flavor = "tap-preferred";
            tapping-term-ms = <150>;
            require-prior-idle-ms = <125>;
            bindings = <&mo>, <&osl>;
            display-name = "tap layer very fast delayed sticky layer";
        };

        /omit-if-no-ref/
        ltSi_sl: layer_tap_very_slow_idle_sticky_layer {
            compatible = "zmk,behavior-hold-tap";
            #binding-cells = <2>;
            flavor = "hold-preferred";
            tapping-term-ms = <500>;
            require-prior-idle-ms = <200>;
            bindings = <&mo>, <&osl>;
            display-name = "layer tap very slow idle sticky layer";
        };

        /omit-if-no-ref/
        hrlSi_sl: tap_layer_very_slow_idle_sticky_layer {
            compatible = "zmk,behavior-hold-tap";
            #binding-cells = <2>;
            flavor = "tap-preferred";
            tapping-term-ms = <500>;
            require-prior-idle-ms = <200>;
            bindings = <&mo>, <&osl>;
            display-name = "tap layer very slow idle sticky layer";
        };

        /omit-if-no-ref/
        ltsi_sl: layer_tap_slow_idle_sticky_layer {
            compatible = "zmk,behavior-hold-tap";
            #binding-cells = <2>;
            flavor = "hold-preferred";
            tapping-term-ms = <300>;
            require-prior-idle-ms = <200>;
            bindings = <&mo>, <&osl>;
            display-name = "layer tap slow idle sticky layer";
        };

        /omit-if-no-ref/
        hrlsi_sl: tap_layer_slow_idle_sticky_layer {
            compatible = "zmk,behavior-hold-tap";
            #binding-cells = <2>;
            flavor = "tap-preferred";
            tapping-term-ms = <300>;
            require-prior-idle-ms = <200>;
            bindings = <&mo>, <&osl>;
            display-name = "tap layer slow idle sticky layer";
        };

        /omit-if-no-ref/
        lti_sl: layer_tap_idle_sticky_layer {
            compatible = "zmk,behavior-hold-tap";
            #binding-cells = <2>;
            flavor = "hold-preferred";
            tapping-term-ms = <250>;
            require-prior-idle-ms = <200>;
            bindings = <&mo>, <&osl>;
            display-name = "layer tap idle sticky layer";
        };

        /omit-if-no-ref/
        hrli_sl: tap_layer_idle_sticky_layer {
            compatible = "zmk,behavior-hold-tap";
            #binding-cells = <2>;
            flavor = "tap-preferred";
            tapping-term-ms = <250>;
            require-prior-idle-ms = <200>;
            bindings = <&mo>, <&osl>;
            display-name = "tap layer idle sticky layer";
        };

        /omit-if-no-ref/
        ltfi_sl: layer_tap_fast_idle_sticky_layer {
            compatible = "zmk,behavior-hold-tap";
            #binding-cells = <2>;
            flavor = "hold-preferred";
            tapping-term-ms = <200>;
            require-prior-idle-ms = <200>;
            bindings = <&mo>, <&osl>;
            display-name = "layer tap fast idle sticky layer";
        };

        /omit-if-no-ref/
        hrlfi_sl: tap_layer_fast_idle_sticky_layer {
            compatible = "zmk,behavior-hold-tap";
            #binding-cells = <2>;
            flavor = "tap-preferred";
            tapping-term-ms = <200>;
            require-prior-idle-ms = <200>;
            bindings = <&mo>, <&osl>;
            display-name = "tap layer fast idle sticky layer";
        };

        /omit-if-no-ref/
        ltFi_sl: layer_tap_very_fast_idle_sticky_layer {
            compatible = "zmk,behavior-hold-tap";
            #binding-cells = <2>;
            flavor = "hold-preferred";
            tapping-term-ms = <150>;
            require-prior-idle-ms = <200>;
            bindings = <&mo>, <&osl>;
            display-name = "layer tap very fast idle sticky layer";
        };

        /omit-if-no-ref/
        hrlFi_sl: tap_layer_very_fast_idle_sticky_layer {
            compatible = "zmk,behavior-hold-tap";
            #binding-cells = <2>;
            flavor = "tap-preferred";
            tapping-term-ms = <150>;
            require-prior-idle-ms = <200>;
            bindings = <&mo>, <&osl>;
            display-name = "tap layer very fast idle sticky layer";
        };

    };
};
